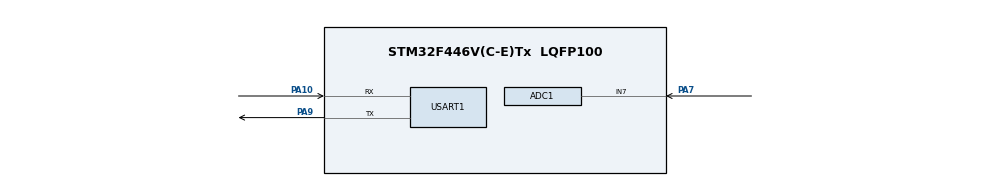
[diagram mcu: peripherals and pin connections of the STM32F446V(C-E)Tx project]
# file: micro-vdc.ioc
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ADC1.Channel-0\#ChannelRegularConversion=ADC_CHANNEL_7
ADC1.ContinuousConvMode=ENABLE
ADC1.NbrOfConversionFlag=1
ADC1.Rank-0\#ChannelRegularConversion=1
ADC1.SamplingTime-0\#ChannelRegularConversion=ADC_SAMPLETIME_3CYCLES
ADC1.master=1
Mcu.Family=STM32F4
Mcu.Name=STM32F446V(C-E)Tx
Mcu.Package=LQFP100
NVIC.PriorityGroup=NVIC_PRIORITYGROUP_4
PA10.Mode=Asynchronous
PA10.Signal=USART1_RX
PA7.Signal=ADCx_IN7
PA9.Mode=Asynchronous
PA9.Signal=USART1_TX
PH0-OSC_IN.Mode=HSE-External-Oscillator
PH0-OSC_IN.Signal=RCC_OSC_IN
PH1-OSC_OUT.Mode=HSE-External-Oscillator
PH1-OSC_OUT.Signal=RCC_OSC_OUT
ProjectManager.HeapSize=0x200
ProjectManager.StackSize=0x400
ProjectManager.TargetToolchain=TrueSTUDIO
RCC.CortexFreq_Value=16000000
RCC.USBFreq_Value=96000000
RCC.VCOOutputFreq_Value=192000000
SH.ADCx_IN7.0=ADC1_IN7,IN7
board=micro-vdc

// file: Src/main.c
/**
  ******************************************************************************
  * File Name          : main.c
  * Description        : Main program body
  ******************************************************************************
  *
  * COPYRIGHT(c) 2017 STMicroelectronics
  *
  * Redistribution and use in source and binary forms, with or without modification,
  * are permitted provided that the following conditions are met:
  *   1. Redistributions of source code must retain the above copyright notice,
  *      this list of conditions and the following disclaimer.
  *   2. Redistributions in binary form must reproduce the above copyright notice,
  *      this list of conditions and the following disclaimer in the documentation
  *      and/or other materials provided with the distribution.
  *   3. Neither the name of STMicroelectronics nor the names of its contributors
  *      may be used to endorse or promote products derived from this software
  *      without specific prior written permission.
  *
  * THIS SOFTWARE IS PROVIDED BY THE COPYRIGHT HOLDERS AND CONTRIBUTORS "AS IS"
  * AND ANY EXPRESS OR IMPLIED WARRANTIES, INCLUDING, BUT NOT LIMITED TO, THE
  * IMPLIED WARRANTIES OF MERCHANTABILITY AND FITNESS FOR A PARTICULAR PURPOSE ARE
  * DISCLAIMED. IN NO EVENT SHALL THE COPYRIGHT HOLDER OR CONTRIBUTORS BE LIABLE
  * FOR ANY DIRECT, INDIRECT, INCIDENTAL, SPECIAL, EXEMPLARY, OR CONSEQUENTIAL
  * DAMAGES (INCLUDING, BUT NOT LIMITED TO, PROCUREMENT OF SUBSTITUTE GOODS OR
  * SERVICES; LOSS OF USE, DATA, OR PROFITS; OR BUSINESS INTERRUPTION) HOWEVER
  * CAUSED AND ON ANY THEORY OF LIABILITY, WHETHER IN CONTRACT, STRICT LIABILITY,
  * OR TORT (INCLUDING NEGLIGENCE OR OTHERWISE) ARISING IN ANY WAY OUT OF THE USE
  * OF THIS SOFTWARE, EVEN IF ADVISED OF THE POSSIBILITY OF SUCH DAMAGE.
  *
  ******************************************************************************
  */
#include "main.h"
#include "stm32f4xx_hal.h"
#include "adc.h"
#include "usart.h"
#include "gpio.h"
#include "temperature_reading.h"

/* USER CODE BEGIN PV */
/* Private variables ---------------------------------------------------------*/
uint32_t adcResult =  0;

/* USER CODE END PV */

void SystemClock_Config(void);
void Error_Handler(void);

/* USER CODE BEGIN PFP */
/* Private function prototypes -----------------------------------------------*/

/* USER CODE END PFP */

/* USER CODE BEGIN 0 */
#define ADC_0V_VALUE 0
#define ADC_1V_VALUE 1241
#define ADC_2V_VALUE 2482
#define ADC_3V_VALUE 3723
/* USER CODE END 0 */

int main(void)
{

  /* MCU Configuration----------------------------------------------------------*/

  /* Reset of all peripherals, Initializes the Flash interface and the Systick. */
  HAL_Init();

  /* Configure the system clock */
  SystemClock_Config();

  /* Initialize all configured peripherals */
  MX_GPIO_Init();
  MX_ADC1_Init();
  MX_USART1_UART_Init();

  /* Infinite loop */
  while (1)
  {
	  TemperatureReading *temp_reading;
	  float temperature;
	  char reading[8];

	  temp_reading = (TemperatureReading*) TEMPERATURE_READING_new(&hadc1);

	  TEMPERATURE_READING_start(temp_reading);
	  temperature = TEMPERATURE_READING_get_temperature(temp_reading);
	  TEMPERATURE_READING_end(temp_reading);

	  // Transforma a temperatura em string e a imprime
	  sprintf(reading, "%.3f", temp_reading->temperature);
	  HAL_UART_Transmit(&huart1, reading, 14,  100);
  }

}

/** System Clock Configuration
*/
void SystemClock_Config(void)
{

  RCC_OscInitTypeDef RCC_OscInitStruct;
  RCC_ClkInitTypeDef RCC_ClkInitStruct;

    /**Configure the main internal regulator output voltage
    */
  __HAL_RCC_PWR_CLK_ENABLE();

  __HAL_PWR_VOLTAGESCALING_CONFIG(PWR_REGULATOR_VOLTAGE_SCALE3);

    /**Initializes the CPU, AHB and APB busses clocks
    */
  RCC_OscInitStruct.OscillatorType = RCC_OSCILLATORTYPE_HSI;
  RCC_OscInitStruct.HSIState = RCC_HSI_ON;
  RCC_OscInitStruct.HSICalibrationValue = 16;
  RCC_OscInitStruct.PLL.PLLState = RCC_PLL_NONE;
  if (HAL_RCC_OscConfig(&RCC_OscInitStruct) != HAL_OK)
  {
    Error_Handler();
  }

    /**Initializes the CPU, AHB and APB busses clocks
    */
  RCC_ClkInitStruct.ClockType = RCC_CLOCKTYPE_HCLK|RCC_CLOCKTYPE_SYSCLK
                              |RCC_CLOCKTYPE_PCLK1|RCC_CLOCKTYPE_PCLK2;
  RCC_ClkInitStruct.SYSCLKSource = RCC_SYSCLKSOURCE_HSI;
  RCC_ClkInitStruct.AHBCLKDivider = RCC_SYSCLK_DIV1;
  RCC_ClkInitStruct.APB1CLKDivider = RCC_HCLK_DIV1;
  RCC_ClkInitStruct.APB2CLKDivider = RCC_HCLK_DIV1;

  if (HAL_RCC_ClockConfig(&RCC_ClkInitStruct, FLASH_LATENCY_0) != HAL_OK)
  {
    Error_Handler();
  }

    /**Configure the Systick interrupt time
    */
  HAL_SYSTICK_Config(HAL_RCC_GetHCLKFreq()/1000);

    /**Configure the Systick
    */
  HAL_SYSTICK_CLKSourceConfig(SYSTICK_CLKSOURCE_HCLK);

  /* SysTick_IRQn interrupt configuration */
  HAL_NVIC_SetPriority(SysTick_IRQn, 0, 0);
}

void Error_Handler(void)
{
  while(1)
  {
  }
}

/************************ (C) COPYRIGHT STMicroelectronics *****END OF FILE****/
